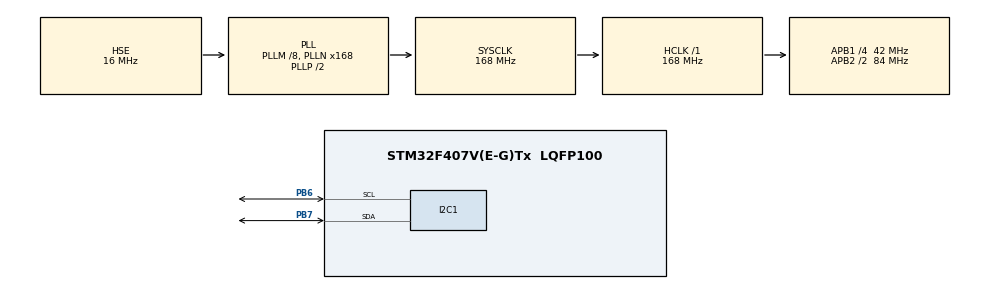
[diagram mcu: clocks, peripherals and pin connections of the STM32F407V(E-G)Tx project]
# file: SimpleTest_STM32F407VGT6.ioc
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Mcu.Family=STM32F4
Mcu.Name=STM32F407V(E-G)Tx
Mcu.Package=LQFP100
NVIC.I2C1_EV_IRQn=true\:0\:0\:false\:false\:true\:true\:true\:true
NVIC.PriorityGroup=NVIC_PRIORITYGROUP_4
PA13.Mode=JTAG_5_pins
PA13.Signal=SYS_JTMS-SWDIO
PA14.Mode=JTAG_5_pins
PA14.Signal=SYS_JTCK-SWCLK
PA15.Mode=JTAG_5_pins
PA15.Signal=SYS_JTDI
PB3.Mode=JTAG_5_pins
PB3.Signal=SYS_JTDO-SWO
PB4.Mode=JTAG_5_pins
PB4.Signal=SYS_JTRST
PB6.Mode=I2C
PB6.Signal=I2C1_SCL
PB7.Mode=I2C
PB7.Signal=I2C1_SDA
PH0-OSC_IN.Mode=HSE-External-Oscillator
PH0-OSC_IN.Signal=RCC_OSC_IN
PH1-OSC_OUT.Mode=HSE-External-Oscillator
PH1-OSC_OUT.Signal=RCC_OSC_OUT
ProjectManager.HeapSize=0x200
ProjectManager.StackSize=0x400
ProjectManager.TargetToolchain=MDK-ARM V5.32
RCC.48MHZClocksFreq_Value=84000000
RCC.AHBFreq_Value=168000000
RCC.APB1CLKDivider=RCC_HCLK_DIV4
RCC.APB1Freq_Value=42000000
RCC.APB1TimFreq_Value=84000000
RCC.APB2CLKDivider=RCC_HCLK_DIV2
RCC.APB2Freq_Value=84000000
RCC.APB2TimFreq_Value=168000000
RCC.CortexFreq_Value=168000000
RCC.EnbaleCSS=true
RCC.HCLKFreq_Value=168000000
RCC.HSE_VALUE=16000000
RCC.HSI_VALUE=16000000
RCC.LSE_VALUE=32768
RCC.PLLM=8
RCC.PLLN=168
RCC.PLLSourceVirtual=RCC_PLLSOURCE_HSE
RCC.SYSCLKFreq_VALUE=168000000
RCC.SYSCLKSource=RCC_SYSCLKSOURCE_PLLCLK
RCC.VCOOutputFreq_Value=336000000
VP_TIM2_VS_ClockSourceINT.Mode=Internal
board=custom

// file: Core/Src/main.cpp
/* USER CODE BEGIN Header */
/**
  ******************************************************************************
  * @file           : main.c
  * @brief          : Main program body
  ******************************************************************************
  * @attention
  *
  * Copyright (c) 2024 STMicroelectronics.
  * All rights reserved.
  *
  * This software is licensed under terms that can be found in the LICENSE file
  * in the root directory of this software component.
  * If no LICENSE file comes with this software, it is provided AS-IS.
  *
  ******************************************************************************
  */
/* USER CODE END Header */
#include "main.h"

/* USER CODE BEGIN Includes */
#include "Wire.h"
#include "I2C_eeprom.h"
/* USER CODE END Includes */

I2C_HandleTypeDef hi2c1;

TIM_HandleTypeDef htim2;

/* USER CODE BEGIN PV */
TimerControl timer(&htim2);
TwoWire wire(&hi2c1);
I2C_eeprom ee(0x50, &wire, &timer);

#pragma pack(1)
struct MyData {
    uint8_t id;
    int16_t value;
    float temperature;
    char name[10];
};
#pragma pack()

float temp;

/* USER CODE END PV */

void SystemClock_Config(void);
static void MX_GPIO_Init(void);
static void MX_I2C1_Init(void);
static void MX_TIM2_Init(void);

int main(void)
{

  /* MCU Configuration--------------------------------------------------------*/

  /* Reset of all peripherals, Initializes the Flash interface and the Systick. */
  HAL_Init();

  /* Configure the system clock */
  SystemClock_Config();

  /* Initialize all configured peripherals */
  MX_GPIO_Init();
  MX_I2C1_Init();
  MX_TIM2_Init();
  /* USER CODE BEGIN 2 */
  timer.init();
  timer.start();
	wire.begin();
	ee.begin();
	if (! ee.isConnected())
	{
		while (1);
	}
/*
  MyData data = {42, 324, 125, "Sensor1"};

  ee.updateBlock(0, reinterpret_cast<const uint8_t *>(&data), sizeof(MyData));

  // Read the structure back from EEPROM
  MyData retrievedData;
  ee.readBlock(0, reinterpret_cast<uint8_t *>(&retrievedData), sizeof(MyData));

  temp = retrievedData.temperature;
	*/
	ee.updateByte(1280000, 123);
	temp = ee.determineSize();
  /* USER CODE END 2 */

  /* Infinite loop */
  while (1)
  {

  }
}

void SystemClock_Config(void)
{
  RCC_OscInitTypeDef RCC_OscInitStruct = {0};
  RCC_ClkInitTypeDef RCC_ClkInitStruct = {0};

  /** Configure the main internal regulator output voltage
  */
  __HAL_RCC_PWR_CLK_ENABLE();
  __HAL_PWR_VOLTAGESCALING_CONFIG(PWR_REGULATOR_VOLTAGE_SCALE1);

  /** Initializes the RCC Oscillators according to the specified parameters
  * in the RCC_OscInitTypeDef structure.
  */
  RCC_OscInitStruct.OscillatorType = RCC_OSCILLATORTYPE_HSE;
  RCC_OscInitStruct.HSEState = RCC_HSE_ON;
  RCC_OscInitStruct.PLL.PLLState = RCC_PLL_ON;
  RCC_OscInitStruct.PLL.PLLSource = RCC_PLLSOURCE_HSE;
  RCC_OscInitStruct.PLL.PLLM = 8;
  RCC_OscInitStruct.PLL.PLLN = 168;
  RCC_OscInitStruct.PLL.PLLP = RCC_PLLP_DIV2;
  RCC_OscInitStruct.PLL.PLLQ = 4;
  if (HAL_RCC_OscConfig(&RCC_OscInitStruct) != HAL_OK)
  {
    Error_Handler();
  }

  /** Initializes the CPU, AHB and APB buses clocks
  */
  RCC_ClkInitStruct.ClockType = RCC_CLOCKTYPE_HCLK|RCC_CLOCKTYPE_SYSCLK
                              |RCC_CLOCKTYPE_PCLK1|RCC_CLOCKTYPE_PCLK2;
  RCC_ClkInitStruct.SYSCLKSource = RCC_SYSCLKSOURCE_PLLCLK;
  RCC_ClkInitStruct.AHBCLKDivider = RCC_SYSCLK_DIV1;
  RCC_ClkInitStruct.APB1CLKDivider = RCC_HCLK_DIV4;
  RCC_ClkInitStruct.APB2CLKDivider = RCC_HCLK_DIV2;

  if (HAL_RCC_ClockConfig(&RCC_ClkInitStruct, FLASH_LATENCY_5) != HAL_OK)
  {
    Error_Handler();
  }

  /** Enables the Clock Security System
  */
  HAL_RCC_EnableCSS();
}

static void MX_I2C1_Init(void)
{

  hi2c1.Instance = I2C1;
  hi2c1.Init.ClockSpeed = 100000;
  hi2c1.Init.DutyCycle = I2C_DUTYCYCLE_2;
  hi2c1.Init.OwnAddress1 = 0;
  hi2c1.Init.AddressingMode = I2C_ADDRESSINGMODE_7BIT;
  hi2c1.Init.DualAddressMode = I2C_DUALADDRESS_DISABLE;
  hi2c1.Init.OwnAddress2 = 0;
  hi2c1.Init.GeneralCallMode = I2C_GENERALCALL_DISABLE;
  hi2c1.Init.NoStretchMode = I2C_NOSTRETCH_DISABLE;
  if (HAL_I2C_Init(&hi2c1) != HAL_OK)
  {
    Error_Handler();
  }

}

static void MX_TIM2_Init(void)
{

  TIM_ClockConfigTypeDef sClockSourceConfig = {0};
  TIM_MasterConfigTypeDef sMasterConfig = {0};

  htim2.Instance = TIM2;
  htim2.Init.Prescaler = 0;
  htim2.Init.CounterMode = TIM_COUNTERMODE_UP;
  htim2.Init.Period = 4294967295;
  htim2.Init.ClockDivision = TIM_CLOCKDIVISION_DIV1;
  htim2.Init.AutoReloadPreload = TIM_AUTORELOAD_PRELOAD_DISABLE;
  if (HAL_TIM_Base_Init(&htim2) != HAL_OK)
  {
    Error_Handler();
  }
  sClockSourceConfig.ClockSource = TIM_CLOCKSOURCE_INTERNAL;
  if (HAL_TIM_ConfigClockSource(&htim2, &sClockSourceConfig) != HAL_OK)
  {
    Error_Handler();
  }
  sMasterConfig.MasterOutputTrigger = TIM_TRGO_RESET;
  sMasterConfig.MasterSlaveMode = TIM_MASTERSLAVEMODE_DISABLE;
  if (HAL_TIMEx_MasterConfigSynchronization(&htim2, &sMasterConfig) != HAL_OK)
  {
    Error_Handler();
  }

}

static void MX_GPIO_Init(void)
{

  /* GPIO Ports Clock Enable */
  __HAL_RCC_GPIOH_CLK_ENABLE();
  __HAL_RCC_GPIOA_CLK_ENABLE();
  __HAL_RCC_GPIOB_CLK_ENABLE();

}

void Error_Handler(void)
{
  __disable_irq();
  while (1)
  {
  }
}
